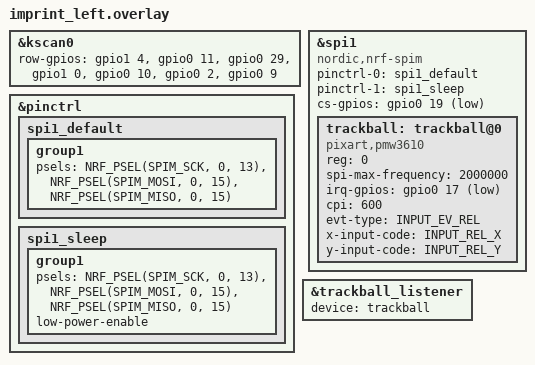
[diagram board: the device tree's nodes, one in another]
#include "imprint.dtsi"

&kscan0 {
    row-gpios
        = <&gpio1 4 GPIO_ACTIVE_HIGH> // row0 from schematic
        , <&gpio0 11 GPIO_ACTIVE_HIGH> // row1 from schematic
        , <&gpio0 29 GPIO_ACTIVE_HIGH> // row2 from schematic
        , <&gpio1 0 GPIO_ACTIVE_HIGH> // row3 from schematic
        , <&gpio0 10 GPIO_ACTIVE_HIGH> // row4 from schematic
        , <&gpio0 2 GPIO_ACTIVE_HIGH> // row5 from schematic
        , <&gpio0 9 GPIO_ACTIVE_HIGH> // row6 from schematic
        ;
};

&pinctrl {
    spi1_default: spi1_default {
        group1 {
            psels = <NRF_PSEL(SPIM_SCK, 0, 13)>,
                <NRF_PSEL(SPIM_MOSI, 0, 15)>,
                <NRF_PSEL(SPIM_MISO, 0, 15)>;
        };
    };

    spi1_sleep: spi1_sleep {
        group1 {
            psels = <NRF_PSEL(SPIM_SCK, 0, 13)>,
                <NRF_PSEL(SPIM_MOSI, 0, 15)>,
                <NRF_PSEL(SPIM_MISO, 0, 15)>;
            low-power-enable;
        };
    };
};

&spi1 {
    status = "okay";
    compatible = "nordic,nrf-spim";
    pinctrl-0 = <&spi1_default>;
    pinctrl-1 = <&spi1_sleep>;
    pinctrl-names = "default", "sleep";
    cs-gpios = <&gpio0 19 GPIO_ACTIVE_LOW>;

    trackball: trackball@0 {
        status = "okay";
        compatible = "pixart,pmw3610";
        reg = <0>;
        spi-max-frequency = <2000000>;
        irq-gpios = <&gpio0 17 (GPIO_ACTIVE_LOW | GPIO_PULL_UP)>;
        cpi = <600>;
        evt-type = <INPUT_EV_REL>;
        x-input-code = <INPUT_REL_X>;
        y-input-code = <INPUT_REL_Y>;
    };
};

// Overrides for the input listener node
&trackball_listener {
    status = "okay";
    device = <&trackball>;
};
